# M55M1 register map
File version: 1.0
Registers are 32-bit, read-write, reset 0x0 unless marked. A register's access mark holds for its fields unless they carry their own. Offsets are from the block's base; [hi:lo] are bit positions; lines under a group give offsets from that group; {n}, {i} and the like mark numbered series; 'fields as' and 'values as' point back to an identical list.

## DAC_NS — DAC Register Map
Base 0x50257000
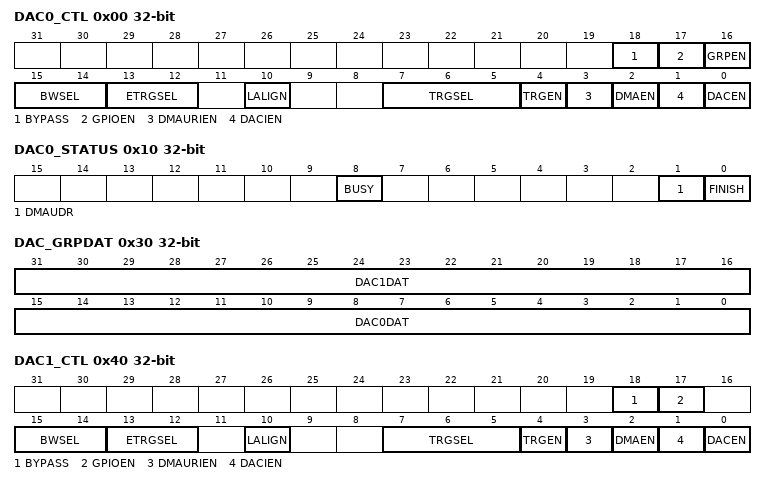
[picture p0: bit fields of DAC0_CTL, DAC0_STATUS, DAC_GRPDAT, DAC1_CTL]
0x00 DAC0_CTL — DAC0 Control Register
  [18] BYPASS — Bypass Buffer Mode
    0=Output voltage buffer Enabled; 1=Output voltage buffer Disabled
  [17] GPIOEN — GPIO Mode Enable Bit
    0=GPIO PIN can output DAC0_OUT voltage; 1=GPIO PIN can be used as other MFP
  [16] GRPEN — DAC Group Mode Enable Bit
    0=DAC0 and DAC1 are not grouped; 1=DAC0 and DAC1 are grouped
  [15:14] BWSEL — DAC Data Bit-width Selection
    0=data is 12 bits; 1=data is 8 bits
  [13:12] ETRGSEL — External Pin Trigger Selection
    0=Low level trigger; 1=High level trigger; 2=Falling edge trigger; 3=Rising edge trigger
  [10] LALIGN — DAC Data Left-aligned Enabled Bit
    0=Right alignment; 1=Left alignment
  [7:5] TRGSEL — Trigger Source Selection
    0=Software trigger; 1=External pin DAC0_ST trigger; {v}=Timer {v-2} trigger (v=2..5); 6=EPWM0 trigger; 7=EPWM1 trigger
  [4] TRGEN — Trigger Mode Enable Bit
    0=DAC event trigger mode Disabled; 1=DAC event trigger mode Enabled
  [3] DMAURIEN — DMA Under-run Interrupt Enable Bit
    0=DMA under-run interrupt Disabled; 1=DMA under-run interrupt Enabled
  [2] DMAEN — DMA Mode Enable Bit
    0=DMA mode Disabled; 1=DMA mode Enabled
  [1] DACIEN — DAC Interrupt Enable Bit
    0=DAC interrupt Disabled; 1=DAC interrupt Enabled
  [0] DACEN — DAC Enable Bit
    0=DAC Disabled; 1=DAC Enabled
0x04 DAC0_SWTRG — DAC0 Software Trigger Control Register
  [0] SWTRG — Software Trigger. Note: User writes this bit to generate one shot pulse and it is cleared to 0 by hardware automatically; reading this bit will always get 0.
    0=Software trigger Disabled; 1=Software trigger Enabled
0x08 DAC0_DAT — DAC0 Data Holding Register
  [15:0] DACDAT — DAC0 12-bit Holding Data. These bits are written by user software which specifies 12-bit conversion data for DAC output. The unused bits (DAC_DAT[3:0] in left-alignment mode and DAC_DAT[15:12] in right alignment mode) are ignored by DAC controller hardware. 12 bit left alignment: user has to load data into DAC_DAT[15:4] bits. 12 bit right alignment: user has to load data into DAC_DAT[11:0] bits.
0x0C DAC0_DATOUT ro — DAC0 Data Output Register
  [11:0] DATOUT — DAC 12-bit Output Data. These bits are current digital data for DAC output conversion. It is loaded from DAC_DAT register and user cannot write it directly.
0x10 DAC0_STATUS
  [8] BUSY ro — DAC Busy Flag (Read Only)
    0=DAC is ready for next conversion; 1=DAC is busy in conversion
  [1] DMAUDR — DMA Under-run Interrupt Flag. Note: User writes 1 to clear this bit.
    0=No DMA under-run error condition occurred; 1=DMA under-run error condition occurred
  [0] FINISH — DAC Conversion Complete Finish Flag. Note: This bit is set to 1 when conversion time counter counts to SETTLET. It is cleared to 0 when DAC starts a new conversion. User writes 1 to clear this bit to 0.
    0=DAC is in conversion state; 1=DAC conversion finish
0x14 DAC0_TCTL — DAC0 Timing Control Register
  [9:0] SETTLET — DAC Output Settling Time. User software needs to write appropriate value to these bits to meet DAC conversion settling time base on PCLK (APB clock) speed. For example, DAC controller clock speed is 80 MHz and DAC conversion settling time is 1 us, SETTLETvalue must be greater than 0x50.
0x30 DAC_GRPDAT — DAC Group Mode Data Holding Register
  [31:16] DAC1DAT — DAC1 12-bit Holding Data. In group mode, user can write these bits for DAC1 12-bit conversion data. The unused bits (DAC_GRPDAT[19:16] in left-alignment mode and DAC_GRPDAT[31:28] in right alignment mode) are ignored by DAC controller hardware. 12 bit left alignment: user has to load data into DAC_GRPDAT[31:20] bits. 12 bit right alignment: user has to load data into DAC_GRPDAT[27:16] bits. Note: In group mode, user can write 12-bit conversion data for DAC1 in DAC_GRPDAT[31:16] or DAC1_DAT[15:0]. The advantage of writing 12-bit conversion data in DAC_GRPDAT[31:16] is that can share one PDMA transfer mechanism. Note: After set GRPEN(DAC0_CTL[16]), user can write 12-bit conversion data for DAC1 in DAC_GRPDAT[31:16]. Note: On the other hand, Write 12-bit conversion data in DAC0_DAT[15:0] or DAC1_DAT[15:0] have individual PDMA transfer mechanism between two DACs
  [15:0] DAC0DAT — DAC0 12-bit Holding Data or DAC01 8-bit Holding Data. These bits are written by user software which specifies 12-bit conversion data for DAC output. The unused bits (DAC_GRPDAT[3:0] in left-alignment mode and DAC_GRPDAT[15:12] in right alignment mode) are ignored by DAC controller hardware. 12 bit left alignment: user has to load data into DAC_GRPDAT[15:4] bits for DAC0. 12 bit right alignment: user has to load data into DAC_GRPDAT[11:0] bits for DAC0. For 8-bit mode, DAC1 data is at DAC_GRPDAT[15:8] and DAC0 data is at DAC_GRPDAT[7:0]. Note: In group mode, user can write 12-bit conversion data for DAC0 in DAC_GRPDAT[15:0] or DAC0_DAT[15:0]. The advantage of writing 12-bit conversion data in DAC_GRPDAT[15:0] is that can share one PDMA transfer mechanism. Note: After set GRPEN(DAC0_CTL[16]), user can write 12-bit conversion data for DAC0 in DAC_GRPDAT[15:0]. Note: On the other hand, write 12-bit conversion data in DAC0_DAT[15:0] or DAC1_DAT[15:0] have individual PDMA transfer mechanism between two DACs
0x40 DAC1_CTL — DAC1 Control Register
  [18] BYPASS — Bypass Buffer Mode
    values as DAC0_CTL.BYPASS
  [17] GPIOEN — GPIO Mode Enable Bit
    0=GPIO PIN can output DAC1_OUT voltage; 1=GPIO PIN can be used as other MFP
  [15:14] BWSEL — DAC Data Bit-width Selection
    0=Data is 12 bits; 1=Data is 8 bits
  [13:12] ETRGSEL — External Pin Trigger Selection
    values as DAC0_CTL.ETRGSEL
  [10] LALIGN — DAC Data Left-aligned Enable Control
    0=Right alignment; 1=Left alignment
  [7:5] TRGSEL — Trigger Source Selection
    0=Software trigger; 1=External pin DAC1_ST trigger; {v}=Timer {v-2} trigger (v=2..5); 6=EPWM0 trigger; 7=EPWM1 trigger
  [4] TRGEN — Trigger Mode Enable Bit
    values as DAC0_CTL.TRGEN
  [3] DMAURIEN — DMA Under-run Interrupt Enable Bit
    values as DAC0_CTL.DMAURIEN
  [2] DMAEN — DMA Mode Enable Bit
    0=DMA mode Disabled; 1=DMA mode Enabled
  [1] DACIEN — DAC Interrupt Enable Bit
    0=DAC interrupt Disabled; 1=DAC interrupt Enabled
  [0] DACEN — DAC Enable Bit
    0=DAC Disabled; 1=DAC Enabled
0x44 DAC1_SWTRG — DAC1 Software Trigger Control Register
  [0] SWTRG — Software Trigger. Note: User writes this bit to generate one shot pulse and it is cleared to 0 by hardware automatically; Reading this bit will always get 0.
    0=Software trigger Disabled; 1=Software trigger Enabled
0x48 DAC1_DAT — DAC1 Data Holding Register
  [15:0] DACDAT — DAC 12-bit Holding Data. These bits are written by user software which specifies 12-bit conversion data for DAC output. The unused bits (DAC_DAT[3:0] in left-alignment mode and DAC_DAT[15:12] in right alignment mode) are ignored by DAC controller hardware. 12 bit left alignment: user has to load data into DAC_DAT[15:4] bits. 12 bit right alignment: user has to load data into DAC_DAT[11:0] bits.
0x4C DAC1_DATOUT ro — DAC1 Data Output Register
  fields as DAC0_DATOUT
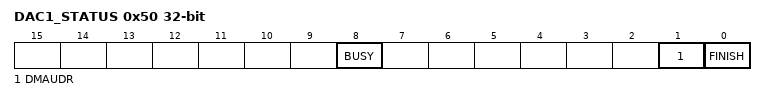
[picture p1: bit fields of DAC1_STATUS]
0x50 DAC1_STATUS
  [8] BUSY ro — DAC Busy Flag (Read Only)
    values as DAC0_STATUS.BUSY
  [1] DMAUDR — DMA Under-run Interrupt Flag. Note: User writes 1 to clear this bit.
    values as DAC0_STATUS.DMAUDR
  [0] FINISH — DAC Conversion Complete Finish Flag. Note: This bit set to 1 when conversion time counter counts to SETTLET. It is cleared to 0 when DAC starts a new conversion. User writes 1 to clear this bit to 0.
    0=DAC is in conversion state; 1=DAC conversion finished
0x54 DAC1_TCTL — DAC1 Timing Control Register
  [9:0] SETTLET — DAC Output Settling Time. User software needs to write appropriate value to these bits to meet DAC conversion settling time base on PCLK (APB clock) speed. For example, DAC controller clock speed is 80 MHz and DAC conversion settling time is 1 us, SETTLET value must be greater than 0x50.
